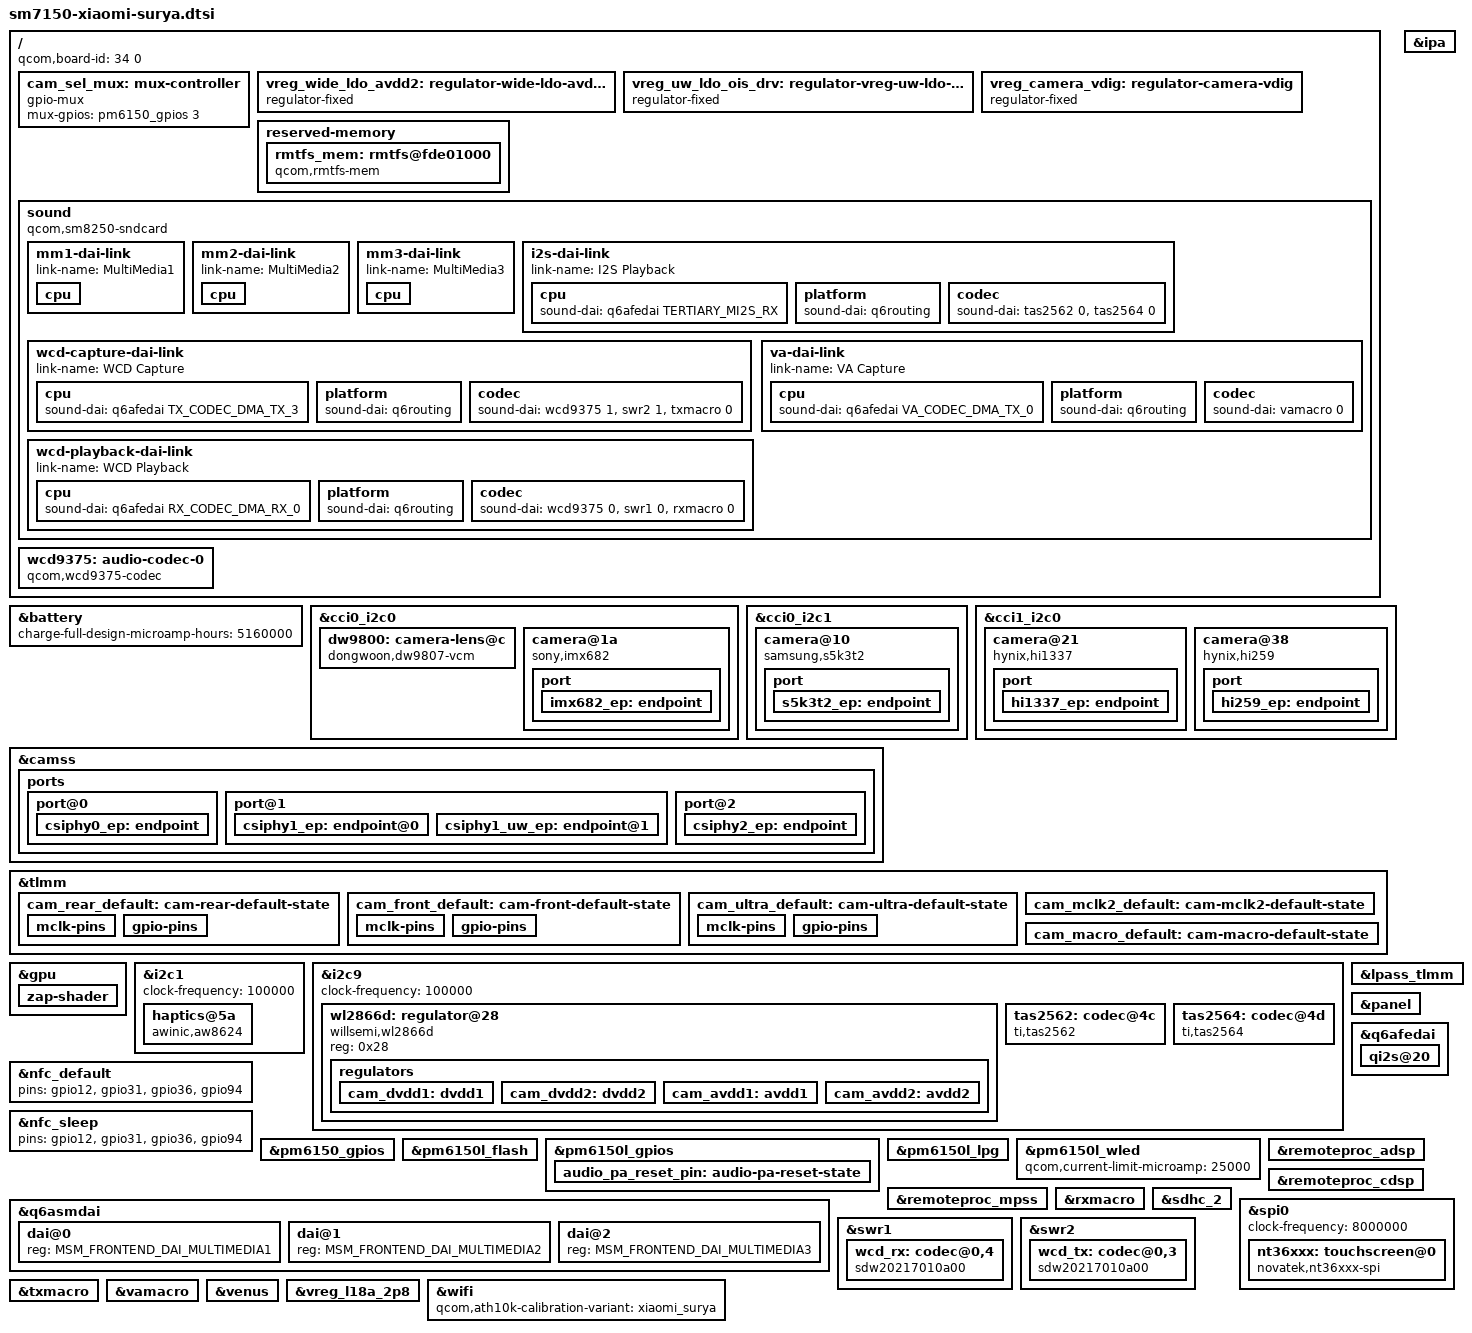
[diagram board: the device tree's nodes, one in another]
// SPDX-License-Identifier: BSD-3-Clause
/*
 * Copyright (c) 2024, Danila Tikhonov <danila@jiaxyga.com>
 * Copyright (c) 2024, David Wronek <davidwronek@gmail.com>
 */

/dts-v1/;

#include <dt-bindings/media/video-interfaces.h>
#include "sm7150-xiaomi-common.dtsi"

/ {
	qcom,board-id = <34 0>;

	/*
	 * CAM_SEL (CAM_SW2_OE_2, pm6150 gpio3) switches the board mux in front of CSIPHY1:
	 * state 0 = front S5K3T2, 1 = ultrawide Hi-1337. A mux controller, not a shared GPIO,
	 * so the two sensor drivers take turns (mux_control_try_select) instead of the line
	 * being left undriven by the shared-GPIO proxy.
	 */
	cam_sel_mux: mux-controller {
		compatible = "gpio-mux";
		#mux-control-cells = <0>;
		mux-gpios = <&pm6150_gpios 3 GPIO_ACTIVE_HIGH>;
	};

	vreg_wide_ldo_avdd2: regulator-wide-ldo-avdd2 {
		compatible = "regulator-fixed";
		regulator-name = "wide_ldo_avdd2";
		regulator-min-microvolt = <2800000>;
		regulator-max-microvolt = <2800000>;

		gpio = <&pm6150l_gpios 4 GPIO_ACTIVE_HIGH>;
		startup-delay-us = <100>;
		enable-active-high;

		vin-supply = <&vreg_bob>;
	};

	vreg_uw_ldo_ois_drv: regulator-vreg-uw-ldo-ois-drv {
		compatible = "regulator-fixed";
		regulator-name = "uw_ldo_ois_drv";
		regulator-min-microvolt = <2800000>;
		regulator-max-microvolt = <2800000>;

		gpio = <&tlmm 65 GPIO_ACTIVE_HIGH>;
		startup-delay-us = <100>;
		enable-active-high;

		vin-supply = <&vreg_bob>;
	};

	vreg_camera_vdig: regulator-camera-vdig {
		compatible = "regulator-fixed";
		regulator-name = "camera_vdig";
		regulator-min-microvolt = <2800000>;
		regulator-max-microvolt = <2800000>;

		gpio = <&pm6150l_gpios 12 GPIO_ACTIVE_HIGH>;
		startup-delay-us = <233>;
		enable-active-high;

		vin-supply = <&vreg_bob>;
	};

	/*
	 * camera_mipi_switch_en (pm6150 gpio2) and CAM_SEL (pm6150 gpio3) drive the board's analog
	 * MIPI switches. No consumer here yet; left unclaimed so the camera bring-up can drive them.
	 */

	reserved-memory {
		rmtfs_mem: rmtfs@fde01000 {
			compatible = "qcom,rmtfs-mem";
			reg = <0 0xfde01000 0 0x200000>;
			no-map;

			qcom,client-id = <1>;
			qcom,vmid = <QCOM_SCM_VMID_MSS_MSA>;
		};
	};

	sound {
		compatible = "qcom,sm8250-sndcard";
		pinctrl-0 = <&ter_mi2s_active>;
		pinctrl-names = "default";
		model = "POCO X3";

		/*
		 * Same wiring as davinci (Mi 9T) and the vendor tree: the
		 * analogue mics sit on AMIC1/AMIC2/AMIC3 of the WCD9375, the
		 * codec ADCs come back over SoundWire inputs 0 and 2.
		 */
		audio-routing = "AMIC1", "MIC BIAS1",
				"AMIC2", "MIC BIAS2",
				"AMIC3", "MIC BIAS3",
				"TX SWR_ADC0", "ADC1_OUTPUT",
				"TX SWR_ADC2", "ADC2_OUTPUT";

		mm1-dai-link {
			link-name = "MultiMedia1";
			cpu {
				sound-dai = <&q6asmdai MSM_FRONTEND_DAI_MULTIMEDIA1>;
			};
		};

		/*
		 * Separate capture frontend (PCM 1), so a source and a sink
		 * can be open at the same time. Playback stays on MultiMedia1.
		 */
		mm2-dai-link {
			link-name = "MultiMedia2";
			cpu {
				sound-dai = <&q6asmdai MSM_FRONTEND_DAI_MULTIMEDIA2>;
			};
		};

		/*
		 * Third frontend (PCM 2) for the earpiece: the top receiver is driven by the
		 * WCD9375 (EAR PA), not by the two TAS amplifiers, which both feed the
		 * bottom loudspeaker.
		 */
		mm3-dai-link {
			link-name = "MultiMedia3";
			cpu {
				sound-dai = <&q6asmdai MSM_FRONTEND_DAI_MULTIMEDIA3>;
			};
		};

		i2s-dai-link {
			link-name = "I2S Playback";
			cpu {
				sound-dai = <&q6afedai TERTIARY_MI2S_RX>;
			};

			platform {
				sound-dai = <&q6routing>;
			};

			codec {
				sound-dai = <&tas2562 0>, <&tas2564 0>;
			};
		};

		/*
		 * Capture through the WCD9375 over the TX SoundWire bus.
		 * DAI 1 of swr2 on purpose: the controller has one dout port,
		 * so its DAI 0 is playback-only and never gets hw_params in a
		 * capture link (see the davinci dtsi for the long version).
		 */
		wcd-capture-dai-link {
			link-name = "WCD Capture";

			cpu {
				sound-dai = <&q6afedai TX_CODEC_DMA_TX_3>;
			};

			platform {
				sound-dai = <&q6routing>;
			};

			codec {
				sound-dai = <&wcd9375 1>, <&swr2 1>, <&txmacro 0>;
			};
		};

		/* Playback through the WCD9375 over the RX SoundWire bus (earpiece, headphones) */
		wcd-playback-dai-link {
			link-name = "WCD Playback";

			cpu {
				sound-dai = <&q6afedai RX_CODEC_DMA_RX_0>;
			};

			platform {
				sound-dai = <&q6routing>;
			};

			codec {
				sound-dai = <&wcd9375 0>, <&swr1 0>, <&rxmacro 0>;
			};
		};

		va-dai-link {
			link-name = "VA Capture";

			cpu {
				sound-dai = <&q6afedai VA_CODEC_DMA_TX_0>;
			};

			platform {
				sound-dai = <&q6routing>;
			};

			codec {
				sound-dai = <&vamacro 0>;
			};
		};
	};

	/*
	 * WCD9375 audio codec. Reset is LPI GPIO 6 ("WCD9375_RST_N" in the
	 * gpio-line-names below). Supplies and mic bias levels are taken from
	 * Xiaomi's vendor tree for surya (sm6150-audio-overlay.dtsi): L10A for
	 * rxtx and px, L15A for the buck, BOB for the mic bias, and all three
	 * mic biases at 2700 mV (davinci uses 2750/1800/2750).
	 */
	wcd9375: audio-codec-0 {
		compatible = "qcom,wcd9375-codec";

		reset-gpios = <&lpass_tlmm 6 GPIO_ACTIVE_LOW>;

		vdd-buck-supply = <&vreg_l15a_1p8>;
		vdd-rxtx-supply = <&vreg_l10a_1p8>;
		vdd-px-supply = <&vreg_l10a_1p8>;
		vdd-mic-bias-supply = <&vreg_bob>;

		qcom,micbias1-microvolt = <2700000>;
		qcom,micbias2-microvolt = <2700000>;
		qcom,micbias3-microvolt = <2700000>;

		/* headset button detection (MBHC) thresholds, as sc7280-idp: without them
		 * the codec driver logs "missing qcom,mbhc-buttons-vthreshold-microvolt" */
		qcom,mbhc-buttons-vthreshold-microvolt = <75000 150000 237000 500000 500000
							  500000 500000 500000>;
		qcom,mbhc-headset-vthreshold-microvolt = <1700000>;
		qcom,mbhc-headphone-vthreshold-microvolt = <50000>;

		qcom,rx-device = <&wcd_rx>;
		qcom,tx-device = <&wcd_tx>;

		#sound-dai-cells = <1>;
	};
};

&battery {
	charge-full-design-microamp-hours = <5160000>;
};

&cci0_i2c0 {
	/*
	 * Main 64MP camera (IMX682, C-PHY: three trios on CSIPHY0) and its focus actuator.
	 * Ported from woodyst/surya-pmos (0044, 0110, 0112, 0115). 0x50 is the module EEPROM.
	 */
	dw9800: camera-lens@c {
		compatible = "dongwoon,dw9807-vcm";
		reg = <0x0c>;
		/* the coil driver hangs off uw_ldo_ois_drv; without it the lens never moves */
		vcc-supply = <&vreg_uw_ldo_ois_drv>;
	};

	camera@1a {
		compatible = "sony,imx682";
		reg = <0x1a>;

		reset-gpios = <&tlmm 25 GPIO_ACTIVE_LOW>;
		standby-gpios = <&tlmm 66 GPIO_ACTIVE_HIGH>;
		pinctrl-names = "default";
		pinctrl-0 = <&cam_rear_default>;

		lens-focus = <&dw9800>;

		/* factory sensor-position-roll 90 is measured the other way: 270 is upright */
		rotation = <270>;
		orientation = <1>;	/* back */

		clocks = <&camcc CAMCC_MCLK1_CLK>;
		assigned-clocks = <&camcc CAMCC_MCLK1_CLK>;
		assigned-clock-rates = <19200000>;

		dovdd-supply = <&vreg_l13a_1p8>;
		avdd-supply = <&cam_avdd2>;
		avdd2-supply = <&vreg_wide_ldo_avdd2>;
		dvdd-supply = <&cam_dvdd2>;

		port {
			imx682_ep: endpoint {
				remote-endpoint = <&csiphy0_ep>;
				/* CSI_SIGNALING_MODE reads 0x03: C-PHY, three trios */
				bus-type = <MEDIA_BUS_TYPE_CSI2_CPHY>;
				data-lanes = <0 1 2>;
				link-frequencies = /bits/ 64 <953600000>;
			};
		};
	};
};

&cci0_i2c1 {
	/* OmniVision ov02b1b Depth @ 3c (8-bit 0x78) */

	/*
	 * Front 20MP camera (S5K3T2, D-PHY, 4 lanes on CSIPHY1). The factory DT puts it on
	 * cci-device 0 / cci-master 1. CSIPHY1 is shared with the ultrawide through a board
	 * mux, CAM_SW2_OE_2 = pm6150 gpio3. From woodyst/surya-pmos (0048, 0112).
	 */
	camera@10 {
		compatible = "samsung,s5k3t2";
		reg = <0x10>;

		reset-gpios = <&tlmm 23 GPIO_ACTIVE_LOW>;
		mux-controls = <&cam_sel_mux>;	/* CSIPHY1 board mux */
		pinctrl-names = "default";
		pinctrl-0 = <&cam_front_default>;

		/* factory roll 270, front: 90 was upside down on the phone, 270 is upright */
		rotation = <270>;
		orientation = <0>;	/* front */

		clocks = <&camcc CAMCC_MCLK0_CLK>;
		assigned-clocks = <&camcc CAMCC_MCLK0_CLK>;
		assigned-clock-rates = <19200000>;

		dovdd-supply = <&vreg_l13a_1p8>;
		avdd-supply = <&cam_avdd1>;
		avdd2-supply = <&vreg_camera_vdig>;

		port {
			s5k3t2_ep: endpoint {
				remote-endpoint = <&csiphy1_ep>;
				data-lanes = <0 1 2 3>;
				link-frequencies = /bits/ 64 <896000000>;
			};
		};
	};
};

&cci1_i2c0 {
	/*
	 * Ultrawide 13MP (Hi-1337, D-PHY, 4 lanes on CSIPHY1, shared with the front camera
	 * through the CAM_SEL mux, high = this sensor). 8-bit address 0x42 in the CamX module.
	 */
	camera@21 {
		compatible = "hynix,hi1337";
		reg = <0x21>;

		reset-gpios = <&tlmm 24 GPIO_ACTIVE_LOW>;
		mux-controls = <&cam_sel_mux>;	/* CSIPHY1 board mux */
		pinctrl-names = "default";
		pinctrl-0 = <&cam_ultra_default>;

		/* factory roll like the main camera's: 270 */
		rotation = <270>;
		orientation = <1>;	/* back */

		clocks = <&camcc CAMCC_MCLK3_CLK>;
		assigned-clocks = <&camcc CAMCC_MCLK3_CLK>;
		assigned-clock-rates = <19200000>;

		dovdd-supply = <&vreg_l13a_1p8>;
		avdd-supply = <&cam_avdd1>;
		dvdd-supply = <&cam_dvdd1>;

		port {
			hi1337_ep: endpoint {
				remote-endpoint = <&csiphy1_uw_ep>;
				data-lanes = <0 1 2 3>;
				link-frequencies = /bits/ 64 <720000000 360000000>;
			};
		};
	};


	/* macro: fixed focus, 1 lane on CSIPHY2 (shared with the depth camera) */
	camera@38 {
		compatible = "hynix,hi259";
		reg = <0x38>;

		clocks = <&camcc CAMCC_MCLK2_CLK>;
		assigned-clocks = <&camcc CAMCC_MCLK2_CLK>;
		assigned-clock-rates = <19200000>;

		reset-gpios = <&tlmm 64 GPIO_ACTIVE_LOW>;
		enable-gpios = <&tlmm 57 GPIO_ACTIVE_HIGH>;
		pinctrl-names = "default";
		pinctrl-0 = <&cam_mclk2_default &cam_macro_default>;

		dovdd-supply = <&vreg_l13a_1p8>;
		avdd-supply = <&cam_avdd1>;

		orientation = <1>;
		/* factory roll 90; like the main camera, 270 is upright on the phone */
		rotation = <270>;

		port {
			hi259_ep: endpoint {
				data-lanes = <1>;
				link-frequencies = /bits/ 64 <390400000>;
				remote-endpoint = <&csiphy2_ep>;
			};
		};
	};
};

&camss {
	ports {
		/* CSIPHY0: main IMX682, C-PHY */
		port@0 {
			csiphy0_ep: endpoint {
				bus-type = <MEDIA_BUS_TYPE_CSI2_CPHY>;
				data-lanes = <0 1 2>;
				remote-endpoint = <&imx682_ep>;
			};
		};

		/* CSIPHY1: front S5K3T2 (muxed with the ultrawide) */
		port@1 {
			#address-cells = <1>;
			#size-cells = <0>;

			csiphy1_ep: endpoint@0 {
				reg = <0>;
				clock-lanes = <7>;
				data-lanes = <0 1 2 3>;
				remote-endpoint = <&s5k3t2_ep>;
			};

			/* ultrawide: same lane layout as the front, selected by CAM_SEL */
			csiphy1_uw_ep: endpoint@1 {
				reg = <1>;
				clock-lanes = <7>;
				data-lanes = <0 1 2 3>;
				remote-endpoint = <&hi1337_ep>;
			};
		};

		port@2 {
			/*
			 * Combo mode, as the vendor CamX module sets it up (laneAssign 0x2, isComboMode 1):
			 * CSIPHY2 is shared with the depth camera on lanes 0-1, the macro sends on data
			 * lane 2 with its clock on lane 3.
			 */
			csiphy2_ep: endpoint {
				clock-lanes = <3>;
				data-lanes = <2>;
				bus-type = <MEDIA_BUS_TYPE_CSI2_DPHY>;
				remote-endpoint = <&hi259_ep>;
			};
		};
	};
};

&tlmm {
	cam_rear_default: cam-rear-default-state {
		mclk-pins {
			pins = "gpio14";
			function = "cam_mclk";
			drive-strength = <2>;
			bias-disable;
		};

		gpio-pins {
			pins = "gpio25", "gpio66";
			function = "gpio";
			drive-strength = <2>;
			bias-disable;
		};
	};

	cam_front_default: cam-front-default-state {
		mclk-pins {
			pins = "gpio13";
			function = "cam_mclk";
			drive-strength = <2>;
			bias-disable;
		};

		gpio-pins {
			pins = "gpio23";
			function = "gpio";
			drive-strength = <2>;
			bias-disable;
		};
	};

	cam_ultra_default: cam-ultra-default-state {
		mclk-pins {
			pins = "gpio16";
			function = "cam_mclk";
			drive-strength = <2>;
			bias-disable;
		};

		gpio-pins {
			pins = "gpio24";
			function = "gpio";
			drive-strength = <2>;
			bias-disable;
		};
	};

	cam_mclk2_default: cam-mclk2-default-state {
		pins = "gpio15";
		function = "cam_mclk";
		drive-strength = <2>;
		bias-disable;
	};

	/* macro reset (gpio64) and CHIP_EN (gpio57) */
	cam_macro_default: cam-macro-default-state {
		pins = "gpio57", "gpio64";
		function = "gpio";
		drive-strength = <2>;
		bias-disable;
	};
};

&gpu {
	zap-shader {
		firmware-name = "qcom/sm7150/xiaomi/surya/a615_zap.mbn";
	};
};

&i2c1 {
	clock-frequency = <100000>;
	status = "okay";

	haptics@5a {
		compatible = "awinic,aw8624";
		reg = <0x5a>;
		interrupts-extended = <&tlmm 26 IRQ_TYPE_EDGE_FALLING>;
		reset-gpios = <&tlmm 63 GPIO_ACTIVE_HIGH>;

		awinic,f0-preset = <2050>;
		awinic,f0-coefficient = <260>;
		awinic,f0-calibration-percent = <7>;
		awinic,drive-level = <100>;

		awinic,f0-detection-play-time = <9>;
		awinic,f0-detection-wait-time = <5>;
		awinic,f0-detection-repeat = <1>;
		awinic,f0-detection-trace = <15>;

		awinic,boost-debug = /bits/ 8 <0x1b 0x1b 0x16>; // ?
		awinic,tset = /bits/ 8 <0x11>;
		awinic,r-spare = /bits/ 8 <0x68>;

		awinic,bemf-upper-threshold = <4000>; // ?
		awinic,bemf-lower-threshold = <2500>; // ?
	};
};

&i2c9 {
	clock-frequency = <100000>;
	status = "okay";

	/* camera LDOs (Will Semiconductor WL2866D); enabled by pm6150l gpio1, already high at boot */
	wl2866d: regulator@28 {
		compatible = "willsemi,wl2866d";
		reg = <0x28>;

		regulators {
			cam_dvdd1: dvdd1 {
				regulator-name = "cam_dvdd1";
				regulator-min-microvolt = <1104000>;
				regulator-max-microvolt = <1200000>;
			};

			cam_dvdd2: dvdd2 {
				regulator-name = "cam_dvdd2";
				regulator-min-microvolt = <1104000>;
				regulator-max-microvolt = <1200000>;
			};

			/* front S5K3T2, depth, macro Hi-259, ultrawide Hi-1337 */
			cam_avdd1: avdd1 {
				regulator-name = "cam_avdd1";
				regulator-min-microvolt = <2800000>;
				regulator-max-microvolt = <2800000>;
			};

			/* main IMX682 */
			cam_avdd2: avdd2 {
				regulator-name = "cam_avdd2";
				regulator-min-microvolt = <2900000>;
				regulator-max-microvolt = <2900000>;
			};
		};
	};

	tas2562: codec@4c { /* SPK */
		compatible = "ti,tas2562";
		reg = <0x4c>;
		#sound-dai-cells = <1>;
		interrupt-parent = <&tlmm>;
		interrupts = <30 IRQ_TYPE_NONE>;
		shutdown-gpios = <&tlmm 91 GPIO_ACTIVE_HIGH>;
		ti,imon-slot-no = <0>;
		ti,vmon-slot-no = <2>;
		sound-name-prefix = "Right";
	};

	tas2564: codec@4d { /* EAR */
		compatible = "ti,tas2564";
		reg = <0x4d>;
		#sound-dai-cells = <1>;
		pinctrl-names = "default";
		pinctrl-0 = <&audio_pa_reset_pin>;
		interrupt-parent = <&tlmm>;
		interrupts = <58 IRQ_TYPE_NONE>;
		shutdown-gpios = <&pm6150l_gpios 8 GPIO_ACTIVE_HIGH>;
		ti,imon-slot-no = <1>;
		ti,vmon-slot-no = <3>;
		sound-name-prefix = "Left";
	};

	/* ti,bq25968 (charger) @ 65 */
};

&ipa {
	firmware-name = "qcom/sm7150/xiaomi/surya/ipa_fws.mbn";
};

&lpass_tlmm {
	gpio-line-names = "SWR_TX_CLK", /* GPIO_0 */
			  "SWR_TX_DATA0",
			  "SWR_TX_DATA1",
			  "SWR_RX_CLK",
			  "SWR_RX_DATA0",
			  "SWR_RX_DATA1",
			  "WCD9375_RST_N",
			  "NC",
			  "NC",
			  "NC",
			  "NC", /* GPIO_10 */
			  "NC",
			  "LPI_QCA_SB_DATA",
			  "LPI_QCA_SB_CLK";
};

&nfc_default {
	pins = "gpio12", "gpio31", "gpio36", "gpio94";
};

&nfc_sleep {
	pins = "gpio12", "gpio31", "gpio36", "gpio94";
};

&panel {
	vddio-supply = <&vreg_l18a_2p8>;
	/delete-property/ vdd3p3-supply;

	backlight = <&pm6150l_wled>;

	pinctrl-0 = <&panel_reset_pin &panel_te_pin &panel_esd_pin>;
};

&pm6150_gpios {
	gpio-line-names = "BOARD_ADC0", /* GPIO_1 */
			  "NC",
			  "CAM_SW2_OE_2",
			  "CAM_2M_DEPTH_IOVDD1P8_EN",
			  "SLB",
			  "PWDN",
			  "NC",
			  "WCSS_PWR_REQ",
			  "NC",
			  "PL_EN"; /* GPIO_10 */
};

&pm6150l_flash {
	status = "okay";
};

&pm6150l_gpios {
	gpio-line-names = "8M/13M_DVDD_1P1_EN", /* GPIO_1 */
			  "KYPD_VOLP_N",
			  "NC",
			  "64M_AVDD0_1P8_EN",
			  "LCD_NTC",
			  "BOARD_ADC1",
			  "SLB",
			  "AUDIO_PA_RST2",
			  "DISP0_RESET_N",
			  "NVM_THERM", /* GPIO_10 */
			  "GPIO11_ID",
			  "20M_DVDD1_1P05_EN";

	audio_pa_reset_pin: audio-pa-reset-state {
		pins = "gpio8";
		function = PMIC_GPIO_FUNC_NORMAL;
		output-high;
		input-disable;
		power-source = <1>;
	};
};

&pm6150l_lpg {
	status = "okay";
};

&pm6150l_wled {
	qcom,current-limit-microamp = <25000>;

	status = "okay";
};

&q6afedai {
	qi2s@20 {
		reg = <TERTIARY_MI2S_RX>;
		qcom,sd-lines = <0>;
	};
};

&q6asmdai {
	dai@0 {
		reg = <MSM_FRONTEND_DAI_MULTIMEDIA1>;
	};

	dai@1 {
		reg = <MSM_FRONTEND_DAI_MULTIMEDIA2>;
	};

	dai@2 {
		reg = <MSM_FRONTEND_DAI_MULTIMEDIA3>;
	};
};

&remoteproc_adsp {
	firmware-name = "qcom/sm7150/xiaomi/surya/adsp.mbn";
};

&remoteproc_cdsp {
	firmware-name = "qcom/sm7150/xiaomi/surya/cdsp.mbn";
};

&remoteproc_mpss {
	firmware-name = "qcom/sm7150/xiaomi/surya/modem.mbn";
};

&rxmacro {
	status = "okay";
};

&sdhc_2 {
	status = "okay";
};

&spi0 {
	clock-frequency = <8000000>;
	status = "okay";

	nt36xxx: touchscreen@0 {
		compatible = "novatek,nt36xxx-spi";
		reg = <0>;

		spi-max-frequency = <8000000>;

		pinctrl-0 = <&ts_int_active &ts_reset_active>;
		pinctrl-1 = <&ts_int_suspend &ts_reset_suspend>;
		pinctrl-names = "default", "sleep";

		reset-gpio = <&tlmm 8 GPIO_ACTIVE_HIGH>;
		irq-gpio = <&tlmm 9 IRQ_TYPE_EDGE_FALLING>;

		vio-supply = <&vreg_l18a_2p8>;

		panel = <&panel>;
	};
};

&swr1 {
	status = "okay";

	wcd_rx: codec@0,4 {
		compatible = "sdw20217010a00";
		reg = <0 4>;

		qcom,rx-port-mapping = <1 2 3 4 5>;
		qcom,rx-channel-mapping = /bits/ 8 <1 2 1 1 2 1 1 2>;
	};
};

&swr2 {
	status = "okay";

	wcd_tx: codec@0,3 {
		compatible = "sdw20217010a00";
		reg = <0 3>;

		/*
		 * Master ports start at 2 because the sm7150 TX controller has
		 * one dout port (hence the leading 0xff in swr2's qcom,ports-*
		 * arrays). Twelve channels: adc1, adc2, adc3, dmic0, dmic1,
		 * mbhc, dmic2..dmic7. Identical to davinci.
		 */
		qcom,tx-port-mapping = <2 2 3 4>;
		qcom,tx-channel-mapping = /bits/ 8 <1 2 1 1 2 3 3 4 1 2 3 4>;
	};
};

&tlmm {
	/* Reserved I/Os for FP */
	gpio-reserved-ranges = <59 4>;

	gpio-line-names = "GP_HP_SDA", /* GPIO_0 */
			  "GP_HP_SCL",
			  "NC",
			  "NC",
			  "LCD_ERR_INT_N",
			  "ANT_CHECK",
			  "DS28E16_1_WIRE",
			  "LDM_ID1",
			  "TP_RST",
			  "TP_INT",
			  "LCD_TE", /* GPIO_10 */
			  "ALSPG_INT_N",
			  "NFC_ENABLE",
			  "CAM_MCLK0",
			  "CAM_MCLK1",
			  "CAM_MCLK2",
			  "CAM_MCLK3",
			  "CC_I2C_SDA0",
			  "CC_I2C_SCL0",
			  "CC_I2C_SDA1",
			  "CC_I2C_SCL1", /* GPIO_20 */
			  "CLK_BUFFER_2",
			  "NC",
			  "CAM4_RST_N",
			  "CAM3_RST_N",
			  "CAM1_RST_N",
			  "HAPTIC_INT_N",
			  "CC_I2C_SDA2",
			  "CC_I2C_SCL2",
			  "NC",
			  "AUDIO_INT1",  /* GPIO_30 */
			  "NFC_CLK_REQ",
			  "CLK_BUFFER_3",
			  "CLK_BUFFER_4",
			  "NFC_I2C_SDA",
			  "NFC_I2C_SCL",
			  "NFC_DWL_REQ",
			  "NFC_IRQ",
			  "BT_UART_CTS",
			  "BT_UART_RFR",
			  "BT_UART_TX", /* GPIO_40 */
			  "BT_UART_RX",
			  "SVDD_PWR_REQ",
			  "CHARGER_INT",
			  "DBG_UART_TX",
			  "DBG_UART_RX",
			  "AUDIO_I2C_SDA",
			  "AUDIO_I2C_SCL",
			  "FORCE_USB_BOOT",
			  "TS_SPI_MISO",
			  "TS_SPI_MOSI", /* GPIO_50 */
			  "TS_SPI_CLK",
			  "TS_SPI_CS_N",
			  "LPI_MI2S_1_SCK",
			  "LPI_MI2S_1_WS",
			  "LPI_MI2S_1_DATA0",
			  "LPI_MI2S_1_DATA1",
			  "CHIP_EN",
			  "AUDIO_INT2",
			  "FP_SPI_MISO",
			  "FP_SPI_MOSI", /* GPIO_60 */
			  "FP_SPI_CLK",
			  "FP_SPI_CS",
			  "HAPTIC_RST_N",
			  "CAM5_RST_N",
			  "DRV_VDD2P8_EN",
			  "64M_AF_EN",
			  "SAR_CAP_INI",
			  "CLK_BUFFER_1",
			  "SD_CARD_DET_N",
			  "NC", /* GPIO_70 */
			  "LDM_IDO",
			  "CAM0_RST_N",
			  "WLAN_SW_CTRL",
			  "PRX_TUNER_SW3",
			  "UIM2_DATA",
			  "UIM2_CLK",
			  "UIM2_RESET",
			  "UIM2_PRESENT",
			  "UIM1_DATA",
			  "UIM1_CLK", /* GPIO_80 */
			  "UIM1_RESET",
			  "UIM1_PRESENT",
			  "PRX_TUNER_SW1",
			  "ANT_CHECK_DIV",
			  "WMSS_RESET_N",
			  "GINT1",
			  "GINT2",
			  "8M_AFVDD_2P8_EN",
			  "FP_INT_N",
			  "FP_RESET_N", /* GPIO_90 */
			  "AUDIO_PA_RST1",
			  "NC",
			  "CAM2_RST_N",
			  "SWITCH_SEL1",
			  "DPDT_TUNER_SW",
			  "QLINK_REQUEST",
			  "QLINK_ENABLE",
			  "LNA_PRX_B1_EN",
			  "DRX_TUNER_SW4",
			  "DRX_ANT_EN", /* GPIO_100 */
			  "NC",
			  "IR_EN_SPI_MOSI",
			  "NC",
			  "USB_PHY_PS",
			  "RFFE5_DATA",
			  "RFFE5_CLK",
			  "LNA_DRX_B7B38B41_EN_v2",
			  "MSS_LTE_COXM_TXD",
			  "MSS_LTE_COXM_RXD",
			  "RFFE2_DATA", /* GPIO_110 */
			  "RFFE2_CLK",
			  "RFFE1_DATA",
			  "RFFE1_CLK";
};

&txmacro {
	status = "okay";
};

&vamacro {
	status = "okay";
};

&venus {
	firmware-name = "qcom/sm7150/xiaomi/surya/venus.mbn";
};

&vreg_l18a_2p8 {
	regulator-min-microvolt = <1696000>;
	regulator-max-microvolt = <1904000>;
};

&wifi {
	qcom,ath10k-calibration-variant = "xiaomi_surya";
};
